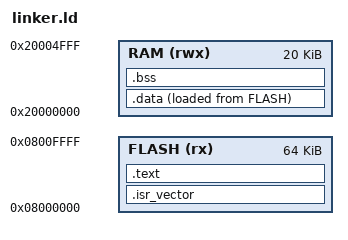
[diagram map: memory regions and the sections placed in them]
/******************************************************************************
 * Linker Script for STM32F103C8T6
 *
 * Author : S.I. SYED ARSHAD
 ******************************************************************************/

ENTRY(Reset_Handler)

/* Memory Map */
MEMORY
{
    FLASH(rx) : ORIGIN = 0x08000000, LENGTH = 64K
    RAM(rwx)  : ORIGIN = 0x20000000, LENGTH = 20K
}

/* Top of Stack */
_estack = ORIGIN(RAM) + LENGTH(RAM);

SECTIONS
{
    /**********************************************************************
     * Interrupt Vector Table
     **********************************************************************/
    .isr_vector :
    {
        . = ALIGN(4);
        KEEP(*(.isr_vector))
        . = ALIGN(4);
    } > FLASH

    /**********************************************************************
     * Program Code and Read-only Data
     **********************************************************************/
    .text :
    {
        . = ALIGN(4);

        *(.text)
        *(.text*)

        *(.rodata)
        *(.rodata*)

        *(.glue_7)
        *(.glue_7t)

        KEEP(*(.init))
        KEEP(*(.fini))

        . = ALIGN(4);
        _etext = .;
    } > FLASH

    /**********************************************************************
     * Initialized Data
     **********************************************************************/
    _sidata = LOADADDR(.data);

    .data :
    {
        . = ALIGN(4);

        _sdata = .;

        *(.data)
        *(.data*)

        . = ALIGN(4);

        _edata = .;

    } > RAM AT > FLASH

    /**********************************************************************
     * Uninitialized Data
     **********************************************************************/
    .bss :
    {
        . = ALIGN(4);

        _sbss = .;

        *(.bss)
        *(.bss*)

        *(COMMON)

        . = ALIGN(4);

        _ebss = .;

    } > RAM

    /**********************************************************************
     * End of RAM
     **********************************************************************/
    . = ALIGN(4);
    _end = .;
}
